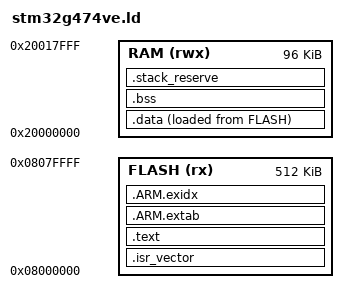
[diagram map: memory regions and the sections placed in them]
ENTRY(Reset_Handler)
MEMORY {
  FLASH (rx) : ORIGIN = 0x08000000, LENGTH = 512K
  RAM (rwx)  : ORIGIN = 0x20000000, LENGTH = 96K
}
_estack = ORIGIN(RAM) + LENGTH(RAM);
SECTIONS {
  .isr_vector : { KEEP(*(.isr_vector)) } > FLASH
  .text : { *(.text*) *(.rodata*) . = ALIGN(4); } > FLASH
  .ARM.extab : { *(.ARM.extab*) } > FLASH
  .ARM.exidx : { __exidx_start = .; *(.ARM.exidx*) __exidx_end = .; } > FLASH
  _sidata = LOADADDR(.data);
  .data : { . = ALIGN(4); _sdata = .; *(.data*) . = ALIGN(4); _edata = .; } > RAM AT > FLASH
  .bss (NOLOAD) : { . = ALIGN(4); _sbss = .; *(.bss*) *(COMMON) . = ALIGN(4); _ebss = .; } > RAM
  .stack_reserve (NOLOAD) : { . = ALIGN(8); . += 4096; } > RAM
  /DISCARD/ : { *(.comment) *(.note*) }
}
ASSERT(_ebss + 4096 <= _estack, "RAM leaves less than 4 KiB for the stack")
